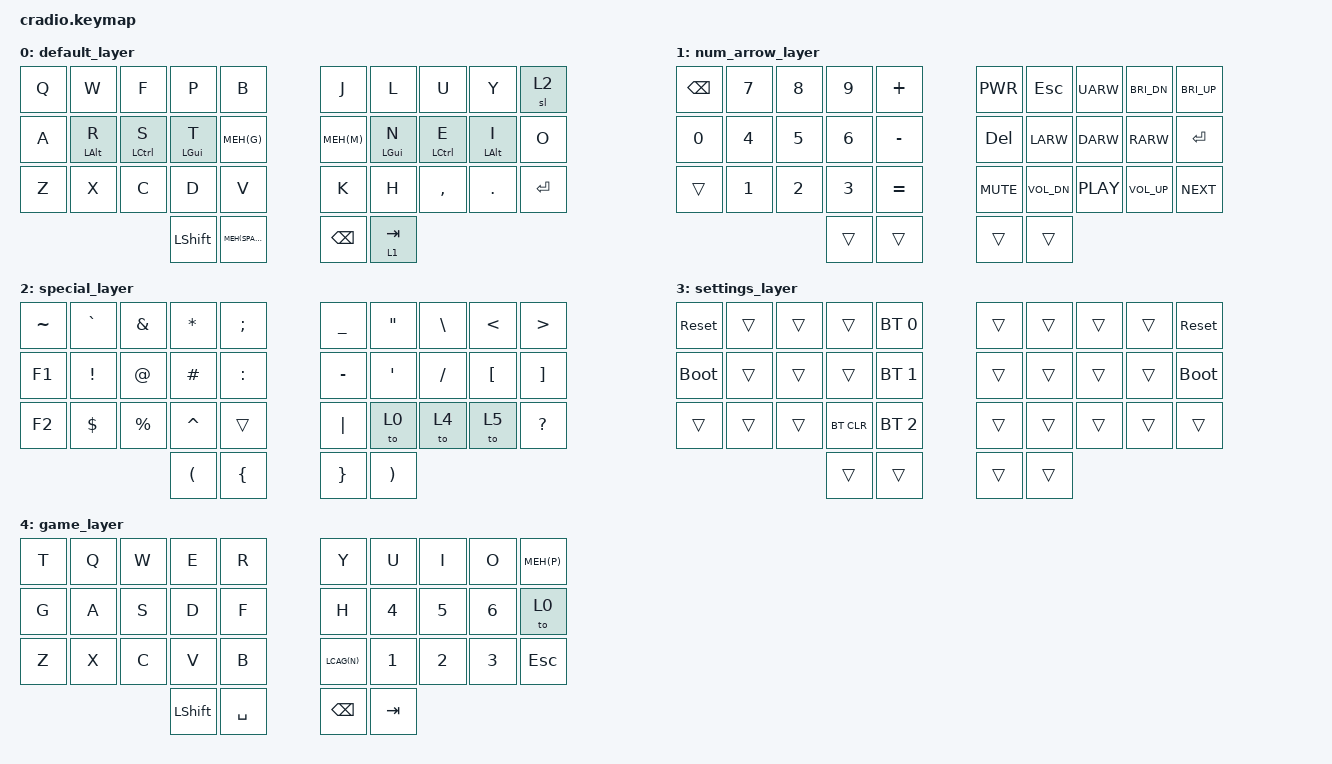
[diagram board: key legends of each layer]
// Copyright (c) 2022 The ZMK Contributors
// SPDX-License-Identifier: MIT

#include <behaviors.dtsi>
#include <dt-bindings/zmk/keys.h>
#include <dt-bindings/zmk/bt.h>

#define MEH(kc) &ht LS(LC(LALT)) kc
#define LCAG(kc) &ht LG(LC(LALT)) kc

&sk {
  quick-release;
};

/ {
    behaviors {
        ht: hold_tap {
            label = "hold_tap";
            compatible = "zmk,behavior-hold-tap";
            #binding-cells = <2>;
            flavor = "tap-preferred";
            tapping-term-ms = <220>;
            quick-tap-ms = <150>;
            require-prior-idle-ms = <100>;
            bindings = <&kp>, <&kp>;
        };
    };

    conditional_layers {
        compatible = "zmk,conditional-layers";
        tri_layer {
            if-layers = <1 2>;
            then-layer = <3>;
        };
    };

    keymap {
        compatible = "zmk,keymap";
        default_layer {
            bindings = <
        //╭──────────┬──────────┬──────────┬──────────┬──────────╮   ╭──────────┬──────────┬──────────┬──────────┬──────────╮
        //│  Q       │  W       │  F       │  P       │  B       │   │  J       │  L       │  U       │  Y       │  c       │
            &kp Q      &kp W      &kp F      &kp P      &kp B          &kp J      &kp L      &kp U      &kp Y      &sl 2
        //├──────────┼──────────┼──────────┼──────────┼──────────┤   ├──────────┼──────────┼──────────┼──────────┼──────────┤
        //│  A       │  R       │  S       │  T       │  G       │   │  M       │  N       │  E       │  I       │ O        │
            &kp A      &ht LALT R  &ht LCTRL S  &ht LGUI T  MEH(G)      MEH(M)     &ht LGUI N  &ht LCTRL E  &ht LALT I  &kp O
        //├──────────┼──────────┼──────────┼──────────┼──────────┤   ├──────────┼──────────┼──────────┼──────────┼──────────┤
        //│  Z       │  X       │  C       │  D       │  V       │   │  K       │  H       │  ,       │  .       │ ENTER    │
            &kp Z      &kp X      &kp C      &kp D      &kp V          &kp K       &kp H      &kp COMMA  &kp DOT  &kp ENTER
        //╰──────────┴──────────┴──────────┼──────────┼──────────┤   ├──────────┼──────────┼──────────┴──────────┴──────────╯
                                            &kp LSHIFT   MEH(SPACE)      &kp BSPC   &lt 1 TAB
        //                                 ╰──────────┴──────────╯   ╰──────────┴──────────╯
            >;
        };
        //default_layer {
        //    bindings = <
        ////╭──────────┬──────────┬──────────┬──────────┬──────────╮   ╭──────────┬──────────┬──────────┬──────────┬──────────╮
        ////│  Q       │  W       │  E       │  R       │  T       │   │  Y       │  U       │  I       │  O       │  P       │
        //    &kp Q      &kp W      &kp E      &kp R      &kp T          &kp Y      &kp U      &kp I      &kp O      MEH(P)
        ////├──────────┼──────────┼──────────┼──────────┼──────────┤   ├──────────┼──────────┼──────────┼──────────┼──────────┤
        ////│  A       │  S       │  D       │  F       │  G       │   │  H       │  J       │  K       │  L       │ LSHIFT   │
        //    &kp A      &kp S      &kp D      &kp F      &kp G          &kp H      &kp J      &kp K      &kp L      &sk LSHFT
        ////├──────────┼──────────┼──────────┼──────────┼──────────┤   ├──────────┼──────────┼──────────┼──────────┼──────────┤
        ////│  Z       │  X       │  C       │  V       │  B       │   │  N       │  M       │ , <      │ . >      │ ENTER      │
        //    &kp Z      &kp X      &kp C      &kp V      &kp B          LCAG(N)   &kp M   &ht LALT COMMA  &ht LCTRL DOT  &ht LGUI ENTER
        ////╰──────────┴──────────┴──────────┼──────────┼──────────┤   ├──────────┼──────────┼──────────┴──────────┴──────────╯
        //                                    &lt 1 TAB   &kp SPACE      &kp BSPC   &sl 2
        ////                                 ╰──────────┴──────────╯   ╰──────────┴──────────╯
        //    >;
        //};

        num_arrow_layer {
            bindings = <
        //╭──────────┬──────────┬──────────┬──────────┬──────────╮   ╭──────────┬──────────┬──────────┬──────────┬──────────╮
        //│ BSPC     │  7       │  8       │  9       │  +       │   │ POWER    │ ESCAPE   │ UP       │ BRIGHT_DN│ BRIGHT_UP│
            &kp BSPC   &kp N7     &kp N8     &kp N9     &kp PLUS       &kp C_PWR  &kp ESC   &kp UARW    &kp C_BRI_DN  &kp C_BRI_UP
        //├──────────┼──────────┼──────────┼──────────┼──────────┤   ├──────────┼──────────┼──────────┼──────────┼──────────┤
        //│ 0        │  4       │  5       │  6       │  -       │   │ DELETE   │ LEFT     │ DOWN     │ RIGHT    │ ENTER    │
            &kp N0     &kp N4     &kp N5     &kp N6     &kp MINUS      &kp DELETE &kp LARW   &kp DARW   &kp RARW  &kp ENTER
        //├──────────┼──────────┼──────────┼──────────┼──────────┤   ├──────────┼──────────┼──────────┼──────────┼──────────┤
        //│          │  1       │  2       │  3       │  =       │   │ MUTE     │ VOL_DN   │ PLAY     │ VOL_UP   │  NEXT    │
            &trans     &kp N1     &kp N2     &kp N3     &kp EQUAL      &kp C_MUTE &kp C_VOL_DN  &kp C_PLAY  &kp C_VOL_UP  &kp C_NEXT
        //╰──────────┴──────────┴──────────┼──────────┼──────────┤   ├──────────┼──────────┼──────────┴──────────┴──────────╯
                                             &trans     &trans         &trans     &trans
        //                                 ╰──────────┴──────────╯   ╰──────────┴──────────╯
            >;
        };

        special_layer {
            bindings = <
        //╭──────────┬──────────┬──────────┬──────────┬──────────╮   ╭──────────┬──────────┬──────────┬──────────┬──────────╮
        //│ ~        │  `       │  &       │  *       │ ;        │   │  _       │  "       │  \       │  <       │  >       │
            &kp TILDE  &kp GRAVE  &kp AMPS   &kp ASTRK  &kp SEMI       &kp UNDER  &kp DQT    &kp BSLH   &kp LT     &kp GT
        //├──────────┼──────────┼──────────┼──────────┼──────────┤   ├──────────┼──────────┼──────────┼──────────┼──────────┤
        //│          │  !       │  @       │  #       │  :       │   │  -       │  '       │  /       │  [       │  ]       │
            &kp F1       &kp EXCL   &kp AT     &kp HASH   &kp COLON      &kp MINUS  &kp SQT    &kp SLASH  &kp LBKT   &kp RBKT
        //├──────────┼──────────┼──────────┼──────────┼──────────┤   ├──────────┼──────────┼──────────┼──────────┼──────────┤
        //│          │  $       │  %       │  ^       │          │   │  |       │          │          │          │  ?       │
            &kp F2     &kp DLLR   &kp PRCNT  &kp CARET  &trans         &kp PIPE   &to 0     &to 4     &to 5     &kp QMARK
        //╰──────────┴──────────┴──────────┼──────────┼──────────┤   ├──────────┼──────────┼──────────┴──────────┴──────────╯
                                             &kp LPAR   &kp LBRC       &kp RBRC   &kp RPAR
        //                                 ╰──────────┴──────────╯   ╰──────────┴──────────╯
            >;
        };

        settings_layer {
            bindings = <
        //╭──────────┬──────────┬──────────┬──────────┬──────────╮   ╭──────────┬──────────┬──────────┬──────────┬──────────╮
        //│ RESET    │          │          │          │PROFILE 0 │   │          │          │          │          │  RESET   │
           &sys_reset  &trans     &trans     &trans    &bt BT_SEL 0    &trans     &trans     &trans     &trans    &sys_reset
        //├──────────┼──────────┼──────────┼──────────┼──────────┤   ├──────────┼──────────┼──────────┼──────────┼──────────┤
        //│BOOTLOADER│          │          │          │PROFILE 1 │   │          │          │          │          │BOOTLOADER│
          &bootloader  &trans     &trans     &trans    &bt BT_SEL 1    &trans     &trans     &trans     &trans    &bootloader
        //├──────────┼──────────┼──────────┼──────────┼──────────┤   ├──────────┼──────────┼──────────┼──────────┼──────────┤
        //│          │          │          │ CLEAR BT │PROFILE 2 │   │          │          │          │          │          │
            &trans     &trans     &trans    &bt BT_CLR &bt BT_SEL 2    &trans     &trans     &trans     &trans     &trans
        //╰──────────┴──────────┴──────────┼──────────┼──────────┤   ├──────────┼──────────┼──────────┴──────────┴──────────╯
                                             &trans     &trans         &trans     &trans
        //                                 ╰──────────┴──────────╯   ╰──────────┴──────────╯
            >;
        };

        game_layer {
            bindings = <
        //╭──────────┬──────────┬──────────┬──────────┬──────────╮   ╭──────────┬──────────┬──────────┬──────────┬──────────╮
        //│  T       │  Q       │  W       │  E       │  R       │   │  Y       │  U       │  I       │  O       │  P       │
            &kp T      &kp Q      &kp W      &kp E      &kp R           &kp Y      &kp U      &kp I      &kp O      MEH(P)
        //├──────────┼──────────┼──────────┼──────────┼──────────┤   ├──────────┼──────────┼──────────┼──────────┼──────────┤
        //│  G       │  A       │  S       │  D       │  F       │   │  H       │  4       │  5       │  6       │          │
            &kp G      &kp A      &kp S      &kp D      &kp F           &kp H      &kp N4     &kp N5    &kp N6      &to 0
        //├──────────┼──────────┼──────────┼──────────┼──────────┤   ├──────────┼──────────┼──────────┼──────────┼──────────┤
        //│  Z       │  X       │  C       │  V       │  B       │   │  N       │  1       │  2       │  3       │  ESCAPE  │
            &kp Z      &kp X      &kp C      &kp V      &kp B          LCAG(N)     &kp N1    &kp N2     &kp N3      &kp ESC
        //╰──────────┴──────────┴──────────┼──────────┼──────────┤   ├──────────┼──────────┼──────────┴──────────┴──────────╯
                                             &kp LSHFT  &kp SPACE      &kp BSPC   &kp TAB
        //                                 ╰──────────┴──────────╯   ╰──────────┴──────────╯
            >;
        };

    };
};
